VERSION "synthetic -- generated by libs/dbc_parser/tests/gen_golden.py"

NS_ :

BS_:

BU_ : ECU

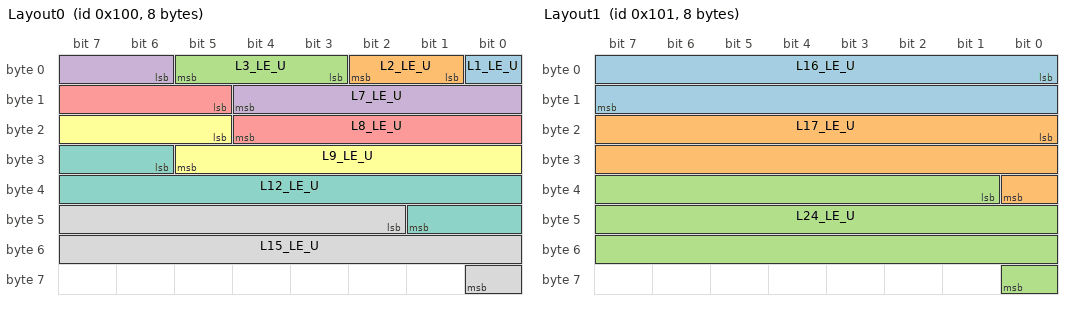
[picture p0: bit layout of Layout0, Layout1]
BO_ 256 Layout0: 8 ECU
 SG_ L1_LE_U : 0|1@1+ (1,0) [0|1] "" ECU
 SG_ L2_LE_U : 1|2@1+ (1,0) [0|3] "" ECU
 SG_ L3_LE_U : 3|3@1+ (1,0) [0|7] "" ECU
 SG_ L7_LE_U : 6|7@1+ (1,0) [0|127] "" ECU
 SG_ L8_LE_U : 13|8@1+ (1,0) [0|255] "" ECU
 SG_ L9_LE_U : 21|9@1+ (1,0) [0|511] "" ECU
 SG_ L12_LE_U : 30|12@1+ (1,0) [0|4095] "" ECU
 SG_ L15_LE_U : 42|15@1+ (1,0) [0|32767] "" ECU

BO_ 257 Layout1: 8 ECU
 SG_ L16_LE_U : 0|16@1+ (1,0) [0|65535] "" ECU
 SG_ L17_LE_U : 16|17@1+ (1,0) [0|131071] "" ECU
 SG_ L24_LE_U : 33|24@1+ (1,0) [0|16777215] "" ECU

BO_ 258 Layout2: 8 ECU
 SG_ L31_LE_U : 0|31@1+ (1,0) [0|2147483647] "" ECU
 SG_ L32_LE_U : 31|32@1+ (1,0) [0|4294967295] "" ECU

BO_ 259 Layout3: 8 ECU
 SG_ L33_LE_U : 0|33@1+ (1,0) [0|8589934591] "" ECU

BO_ 260 Layout4: 8 ECU
 SG_ L53_LE_U : 0|53@1+ (1,0) [0|9007199254740991] "" ECU

BO_ 261 Layout5: 8 ECU
 SG_ L63_LE_U : 0|63@1+ (1,0) [0|9223372036854775807] "" ECU

BO_ 262 Layout6: 8 ECU
 SG_ L64_LE_U : 0|64@1+ (1,0) [0|18446744073709551615] "" ECU

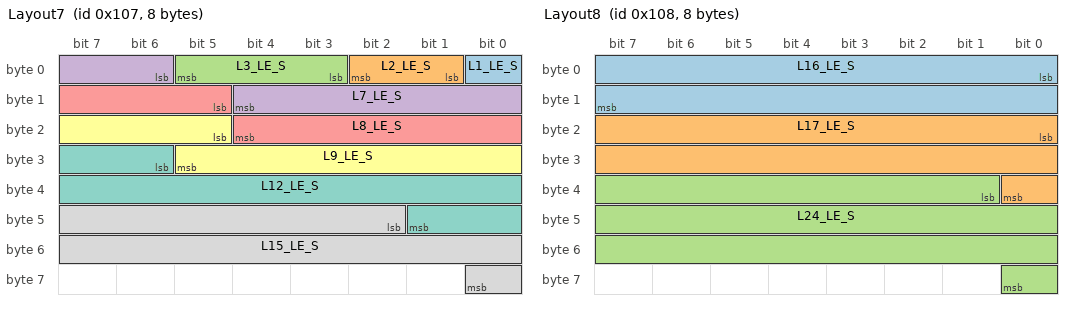
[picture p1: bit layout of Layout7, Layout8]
BO_ 263 Layout7: 8 ECU
 SG_ L1_LE_S : 0|1@1- (1,0) [-1|0] "" ECU
 SG_ L2_LE_S : 1|2@1- (1,0) [-2|1] "" ECU
 SG_ L3_LE_S : 3|3@1- (1,0) [-4|3] "" ECU
 SG_ L7_LE_S : 6|7@1- (1,0) [-64|63] "" ECU
 SG_ L8_LE_S : 13|8@1- (1,0) [-128|127] "" ECU
 SG_ L9_LE_S : 21|9@1- (1,0) [-256|255] "" ECU
 SG_ L12_LE_S : 30|12@1- (1,0) [-2048|2047] "" ECU
 SG_ L15_LE_S : 42|15@1- (1,0) [-16384|16383] "" ECU

BO_ 264 Layout8: 8 ECU
 SG_ L16_LE_S : 0|16@1- (1,0) [-32768|32767] "" ECU
 SG_ L17_LE_S : 16|17@1- (1,0) [-65536|65535] "" ECU
 SG_ L24_LE_S : 33|24@1- (1,0) [-8388608|8388607] "" ECU

BO_ 265 Layout9: 8 ECU
 SG_ L31_LE_S : 0|31@1- (1,0) [-1073741824|1073741823] "" ECU
 SG_ L32_LE_S : 31|32@1- (1,0) [-2147483648|2147483647] "" ECU

BO_ 266 Layout10: 8 ECU
 SG_ L33_LE_S : 0|33@1- (1,0) [-4294967296|4294967295] "" ECU

BO_ 267 Layout11: 8 ECU
 SG_ L53_LE_S : 0|53@1- (1,0) [-4503599627370496|4503599627370495] "" ECU

BO_ 268 Layout12: 8 ECU
 SG_ L63_LE_S : 0|63@1- (1,0) [-4611686018427387904|4611686018427387903] "" ECU

BO_ 269 Layout13: 8 ECU
 SG_ L64_LE_S : 0|64@1- (1,0) [-9223372036854775808|9223372036854775807] "" ECU

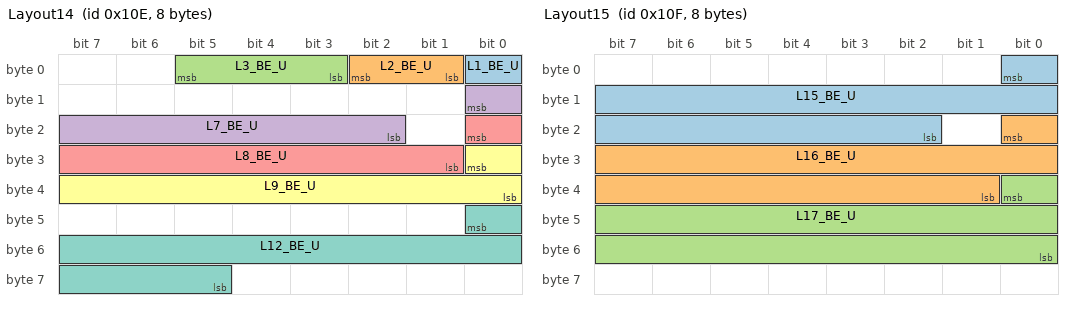
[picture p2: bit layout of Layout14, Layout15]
BO_ 270 Layout14: 8 ECU
 SG_ L1_BE_U : 0|1@0+ (1,0) [0|1] "" ECU
 SG_ L2_BE_U : 2|2@0+ (1,0) [0|3] "" ECU
 SG_ L3_BE_U : 5|3@0+ (1,0) [0|7] "" ECU
 SG_ L7_BE_U : 8|7@0+ (1,0) [0|127] "" ECU
 SG_ L8_BE_U : 16|8@0+ (1,0) [0|255] "" ECU
 SG_ L9_BE_U : 24|9@0+ (1,0) [0|511] "" ECU
 SG_ L12_BE_U : 40|12@0+ (1,0) [0|4095] "" ECU

BO_ 271 Layout15: 8 ECU
 SG_ L15_BE_U : 0|15@0+ (1,0) [0|32767] "" ECU
 SG_ L16_BE_U : 16|16@0+ (1,0) [0|65535] "" ECU
 SG_ L17_BE_U : 32|17@0+ (1,0) [0|131071] "" ECU

BO_ 272 Layout16: 8 ECU
 SG_ L24_BE_U : 0|24@0+ (1,0) [0|16777215] "" ECU
 SG_ L31_BE_U : 24|31@0+ (1,0) [0|2147483647] "" ECU

BO_ 273 Layout17: 8 ECU
 SG_ L32_BE_U : 0|32@0+ (1,0) [0|4294967295] "" ECU

BO_ 274 Layout18: 8 ECU
 SG_ L33_BE_U : 0|33@0+ (1,0) [0|8589934591] "" ECU

BO_ 275 Layout19: 8 ECU
 SG_ L53_BE_U : 0|53@0+ (1,0) [0|9007199254740991] "" ECU

BO_ 276 Layout20: 8 ECU
 SG_ L63_BE_U : 6|63@0+ (1,0) [0|9223372036854775807] "" ECU

BO_ 277 Layout21: 8 ECU
 SG_ L64_BE_U : 7|64@0+ (1,0) [0|18446744073709551615] "" ECU

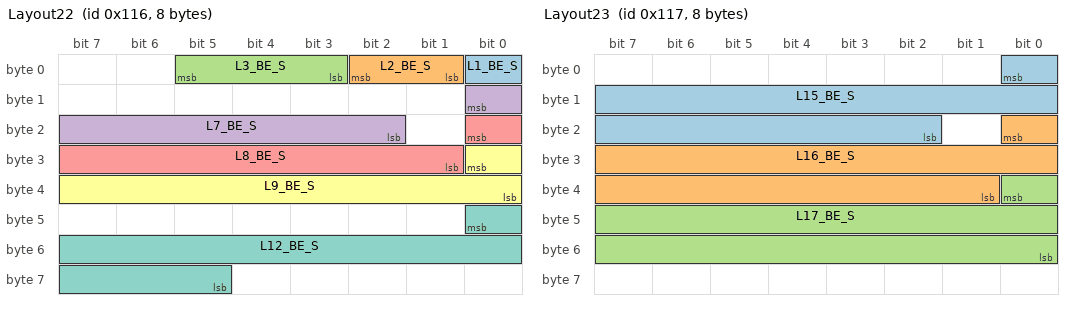
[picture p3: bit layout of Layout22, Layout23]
BO_ 278 Layout22: 8 ECU
 SG_ L1_BE_S : 0|1@0- (1,0) [-1|0] "" ECU
 SG_ L2_BE_S : 2|2@0- (1,0) [-2|1] "" ECU
 SG_ L3_BE_S : 5|3@0- (1,0) [-4|3] "" ECU
 SG_ L7_BE_S : 8|7@0- (1,0) [-64|63] "" ECU
 SG_ L8_BE_S : 16|8@0- (1,0) [-128|127] "" ECU
 SG_ L9_BE_S : 24|9@0- (1,0) [-256|255] "" ECU
 SG_ L12_BE_S : 40|12@0- (1,0) [-2048|2047] "" ECU

BO_ 279 Layout23: 8 ECU
 SG_ L15_BE_S : 0|15@0- (1,0) [-16384|16383] "" ECU
 SG_ L16_BE_S : 16|16@0- (1,0) [-32768|32767] "" ECU
 SG_ L17_BE_S : 32|17@0- (1,0) [-65536|65535] "" ECU

BO_ 280 Layout24: 8 ECU
 SG_ L24_BE_S : 0|24@0- (1,0) [-8388608|8388607] "" ECU
 SG_ L31_BE_S : 24|31@0- (1,0) [-1073741824|1073741823] "" ECU

BO_ 281 Layout25: 8 ECU
 SG_ L32_BE_S : 0|32@0- (1,0) [-2147483648|2147483647] "" ECU

BO_ 282 Layout26: 8 ECU
 SG_ L33_BE_S : 0|33@0- (1,0) [-4294967296|4294967295] "" ECU

BO_ 283 Layout27: 8 ECU
 SG_ L53_BE_S : 0|53@0- (1,0) [-4503599627370496|4503599627370495] "" ECU

BO_ 284 Layout28: 8 ECU
 SG_ L63_BE_S : 6|63@0- (1,0) [-4611686018427387904|4611686018427387903] "" ECU

BO_ 285 Layout29: 8 ECU
 SG_ L64_BE_S : 7|64@0- (1,0) [-9223372036854775808|9223372036854775807] "" ECU
